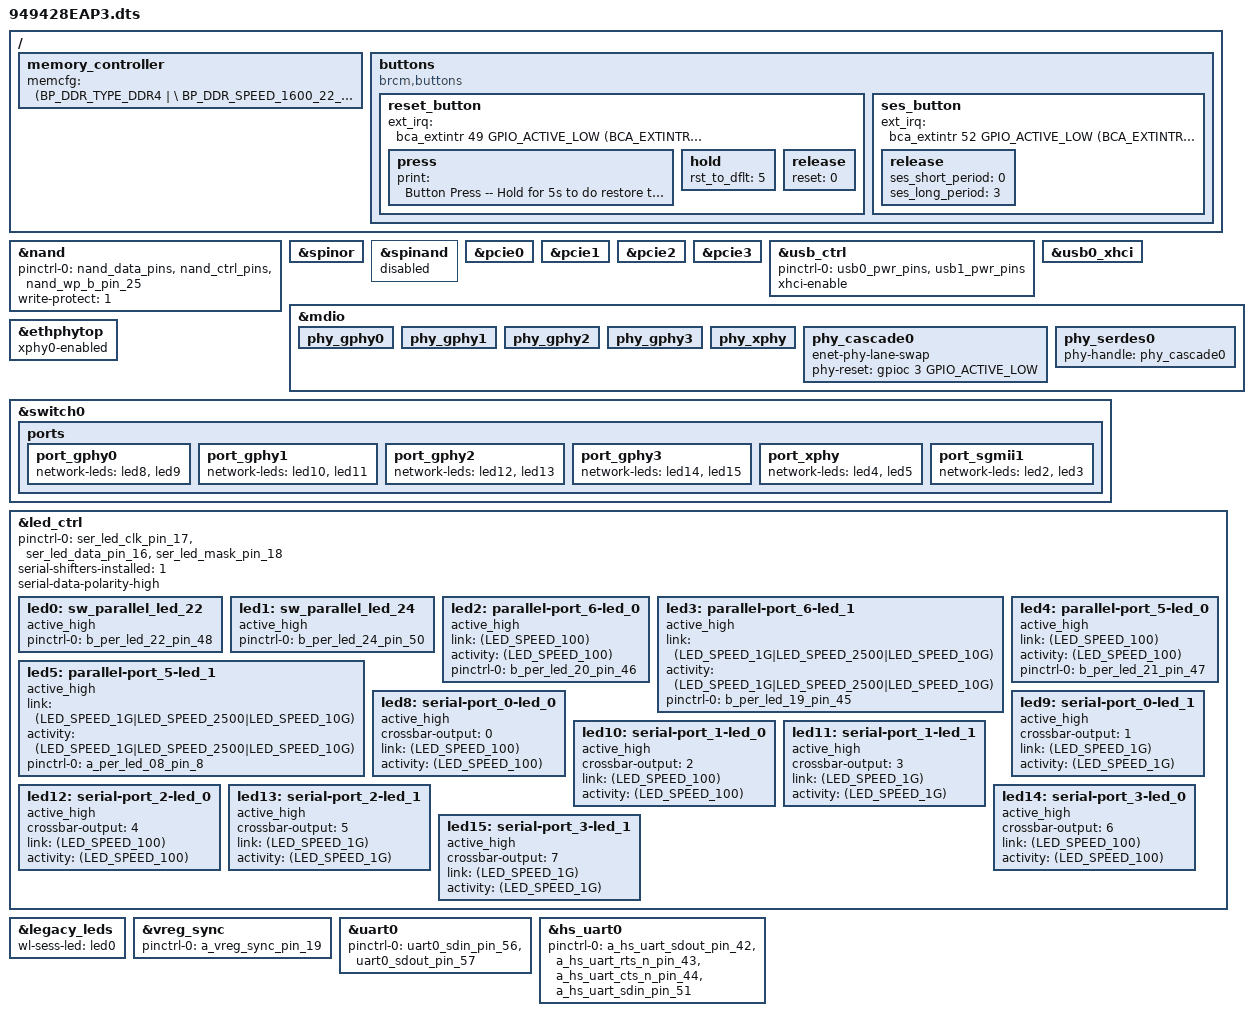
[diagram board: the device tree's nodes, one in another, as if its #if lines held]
#include "6813.dtsi"

/ {
	memory_controller {
		memcfg = <(BP_DDR_TYPE_DDR4       | \
			BP_DDR_SPEED_1600_22_22_22    | \
			BP_DDR_TOTAL_SIZE_2048MB      | \
			BP_DDR_DEVICE_WIDTH_16        | \
			BP_DDR_TOTAL_WIDTH_32BIT      | \
			BP_DDR_6813_DEFAULT          | \
			BP_DDR_CONFIG_DEBUG)>;
	};

	buttons: buttons {
		compatible = "brcm,buttons";
		reset_button {
			ext_irq = <&bca_extintr 49 GPIO_ACTIVE_LOW (BCA_EXTINTR_TYPE_LOW_LEVEL | BCA_EXTINTR_TYPE_SENSE_EDGE)>;
			press {
				print = "Button Press -- Hold for 5s to do restore to default";
			};
			hold {
				rst_to_dflt = <5>;
			};
			release {
				reset = <0>;
			};
		};
		ses_button {
			ext_irq = <&bca_extintr 52 GPIO_ACTIVE_LOW (BCA_EXTINTR_TYPE_LOW_LEVEL | BCA_EXTINTR_TYPE_SENSE_EDGE)>;
			release {
				ses_short_period = <0>;
				ses_long_period = <3>;
			};
		};
	};
};

&nand {
	pinctrl-0 = <&nand_data_pins &nand_ctrl_pins &nand_wp_b_pin_25>;
	write-protect = <1>;
	status = "okay";
};

&spinor {
	status = "okay";
};

&spinand {
	status = "disabled";
};

#if defined(CONFIG_BCM_PCIE_HCD) || defined(CONFIG_BCM_PCIE_HCD_MODULE)

#define PCIE2_REG_GPIO    1    /* SLEEP_2 for vreg_pcie2 node */
#include "../bcm_wlan_regulator.dtsi"

&pcie0 {
	status = "okay";
};
&pcie1 {
	status = "okay";
};
&pcie2 {
	status = "okay";
};
&pcie3 {
	status = "okay";
};
#endif //#if defined(CONFIG_BCM_PCIE_HCD) || defined(CONFIG_BCM_PCIE_HCD_MODULE)

&usb_ctrl {
	pinctrl-names = "default";
	pinctrl-0 = <&usb0_pwr_pins &usb1_pwr_pins>;
	status = "okay";
	xhci-enable;
};
&usb0_xhci {
	status = "okay";
};

&mdio {
	/*
	 * Port PHY mapping:
         * port_gphy0 <----> phy_gphy0
         * port_gphy1 <----> phy_gphy1
         * port_gphy2 <----> phy_gphy2
         * port_gphy3 <----> phy_gphy3
	 * port_xphy <-----> phy_xphy
	 * port_sgmii1 <---> phy_serdes0   - phy_cascade0
	 */
	phy_gphy0 {
		status = "okay";
	};

	phy_gphy1 {
		status = "okay";
	};

	phy_gphy2 {
		status = "okay";
	};

	phy_gphy3 {
		status = "okay";
	};

	phy_xphy {
		status = "okay";
	};

	phy_cascade0 {
		enet-phy-lane-swap;
		phy-reset = <&gpioc 3 GPIO_ACTIVE_LOW>;
		status = "okay";
	};

	phy_serdes0 {
		phy-handle = <&phy_cascade0>;
		status = "okay";
	};

};

&ethphytop {
	xphy0-enabled;
	status = "okay";
};

&switch0 {
	ports {
		port_gphy0 {
			network-leds = <&led8 &led9>;
			status = "okay";
		};

		port_gphy1 {
			network-leds = <&led10 &led11>;
			status = "okay";
		};

		port_gphy2 {
			network-leds = <&led12 &led13>;
			status = "okay";
		};

		port_gphy3 {
			network-leds = <&led14 &led15>;
			status = "okay";
		};

		port_xphy {
			network-leds = <&led4 &led5>;
			status = "okay";
		};

		port_sgmii1 {
			network-leds = <&led2 &led3>;
			status = "okay";
		};
	};
};

&led_ctrl {
	/*
	 * LED mapping:
	 * 0 - WPS (green)
	 * 1 - INET (green, unused)
	 * 2 - sgmii1 (yellow)
	 * 3 - sgmii1 (green)
	 * 4 - xgphy ( yellow)
	 * 5 - xgphy (green)
	 * 8-15 - 4-port switch
	 */
	pinctrl-names = "default";
	pinctrl-0 = <&ser_led_clk_pin_17 &ser_led_data_pin_16 &ser_led_mask_pin_18>;
	serial-shifters-installed = <1>;
	serial-data-polarity-high;
	
	led0: sw_parallel_led_22 {
		active_high;
		pinctrl-0=<&b_per_led_22_pin_48>;
		status = "okay";
	};
	led1: sw_parallel_led_24 {
		active_high;
		pinctrl-0=<&b_per_led_24_pin_50>;
		status = "okay";
	};

	led2: parallel-port_6-led_0 {
		active_high;
		link = <(LED_SPEED_100)>;
		activity = <(LED_SPEED_100)>;
		pinctrl-0=<&b_per_led_20_pin_46>;
		status = "okay";
	};
	led3: parallel-port_6-led_1 {
		active_high;
		link = <(LED_SPEED_1G|LED_SPEED_2500|LED_SPEED_10G)>;
		activity = <(LED_SPEED_1G|LED_SPEED_2500|LED_SPEED_10G)>;
		pinctrl-0=<&b_per_led_19_pin_45>;
		status = "okay";
	};
	led4: parallel-port_5-led_0 {
		active_high;
		link = <(LED_SPEED_100)>;
		activity = <(LED_SPEED_100)>;
		pinctrl-0=<&b_per_led_21_pin_47>;
		status = "okay";
	};
	led5: parallel-port_5-led_1 {
		active_high;
		link = <(LED_SPEED_1G|LED_SPEED_2500|LED_SPEED_10G)>;
		activity = <(LED_SPEED_1G|LED_SPEED_2500|LED_SPEED_10G)>;
		pinctrl-0=<&a_per_led_08_pin_8>;
		status = "okay";
	};
	led8: serial-port_0-led_0 {
		active_high;
		crossbar-output = <0>;
		link = <(LED_SPEED_100)>;
		activity = <(LED_SPEED_100)>;
		status = "okay";
	};
	led9: serial-port_0-led_1 {
		active_high;
		crossbar-output = <1>;
		link = <(LED_SPEED_1G)>;
		activity = <(LED_SPEED_1G)>;
		status = "okay";
	};
	led10: serial-port_1-led_0 {
		active_high;
		crossbar-output = <2>;
		link = <(LED_SPEED_100)>;
		activity = <(LED_SPEED_100)>;
		status = "okay";
	};
	led11: serial-port_1-led_1 {
		active_high;
		crossbar-output = <3>;
		link = <(LED_SPEED_1G)>;
		activity = <(LED_SPEED_1G)>;
		status = "okay";
	};
	led12: serial-port_2-led_0 {
		active_high;
		crossbar-output = <4>;
		link = <(LED_SPEED_100)>;
		activity = <(LED_SPEED_100)>;
		status = "okay";
	};
	led13: serial-port_2-led_1 {
		active_high;
		crossbar-output = <5>;
		link = <(LED_SPEED_1G)>;
		activity = <(LED_SPEED_1G)>;
		status = "okay";
	};
	led14: serial-port_3-led_0 {
		active_high;
		crossbar-output = <6>;
		link = <(LED_SPEED_100)>;
		activity = <(LED_SPEED_100)>;
		status = "okay";
	};
	led15: serial-port_3-led_1 {
		active_high;
		crossbar-output = <7>;
		link = <(LED_SPEED_1G)>;
		activity = <(LED_SPEED_1G)>;
		status = "okay";
	};
};

&legacy_leds {
	wl-sess-led = <&led0>;
};

&vreg_sync {
	pinctrl-0 = <&a_vreg_sync_pin_19>;
	pinctrl-names = "default";
};
&uart0 {
	pinctrl-names = "default";
	pinctrl-0 = <&uart0_sdin_pin_56 &uart0_sdout_pin_57 >;
	status = "okay";
};

&hs_uart0 {
	pinctrl-names = "default";
	pinctrl-0 = <&a_hs_uart_sdout_pin_42 &a_hs_uart_rts_n_pin_43 &a_hs_uart_cts_n_pin_44 &a_hs_uart_sdin_pin_51>;
	status = "okay";
};
